# MEC1701Q register map
Vendor: Microchip Technology; Series: MEC1701; File version: 0
CPU: CM4 r1p0, little endian, MPU, FPU, 3 interrupt priority bits
Registers are 32-bit, read-write, reset 0x0 unless marked. A register's access mark holds for its fields unless they carry their own. Offsets are from the block's base; [hi:lo] are bit positions; 'fields as' and 'values as' point back to an identical list.

## RTC — This is the set of registers that are automatically counted by hardware every 1 second while the block is enabled to run and to update. These registers are: Seconds, Minutes, Hours, Day of Week, Day of Month, Month, and Year.
Base 0x400F5000; register names take the prefix RTC_
0x00 SEC 8-bit — Seconds Register
0x01 SEC_ALARM 8-bit — Seconds Alarm Register
0x02 MIN 8-bit — Minutes Register
0x03 MIN_ALARM 8-bit — Minutes Alarm Register
0x04 HR 8-bit — Hours Register
0x05 HR_ALARM 8-bit — Hours Alarm Register
0x06 DAY_OF_WK 8-bit — Day of Week Register
0x07 DAY_OF_MON 8-bit — Day of Month Register
0x08 MONTH 8-bit
0x09 YEAR 8-bit
0x0A REGA 8-bit — Register A
0x0B REGB 8-bit — Register B
0x0C REGC 8-bit — Register C
0x0D REGD 8-bit — Register D
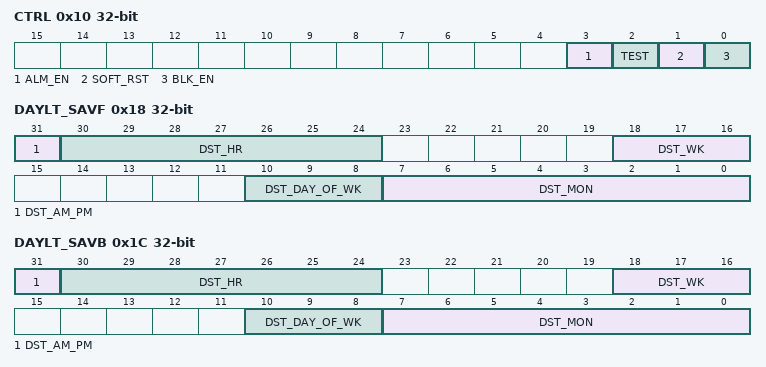
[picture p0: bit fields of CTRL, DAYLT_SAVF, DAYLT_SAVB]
0x10 CTRL — RTC Control Register
  [3] ALM_EN — ALM_EN 1=Enables the Alarm features, 0=Disables the Alarm features
  [2] TEST
  [1] SOFT_RST — SOFT_RST A '1' written to this bit position will trigger the RTC_RST reset, resetting the block and all registers except this one and the Test Register. This bit is self-clearing at the end of the reset, one cycle of Host Bus Clock later, and so requires no waiting.
  [0] BLK_EN — BLK_EN This bit must be '1' in order for the block to function internally. Registers may be initialized first, before setting this bit to '1' to start operation.
0x14 WK_ALARM — Week Alarm Register[7:0] - ALARM_DAY_OF_WEEK This register, if written to a value in the range 1- -7, will inhibit the Alarm interrupt unless this field matches the contents of the Day of Week Register also.
0x18 DAYLT_SAVF — Daylight Savings Forward Register
  [31] DST_AM_PM — This bit selects AM vs. PM, to match bit[7] of the Hours Register if 12-Hour mode is selected in Register B at the time of writing.
  [30:24] DST_HR — This field holds the matching value for bits[6:0] of the Hours register. The written value will be interpreted according to the 24/12 Hour mode and DM mode settings at the time of writing.
  [18:16] DST_WK — 5=Last week of month, 4 =Fourth week of month, 3=Third week of month, 2=Second week of month, 1=First week of month
  [10:8] DST_DAY_OF_WK — This field matches the Day of Week Register bits[2:0].
  [7:0] DST_MON — This field matches the Month Register.
0x1C DAYLT_SAVB — Daylight Savings Backward Register
  fields as DAYLT_SAVF

## TACH0 — This block monitors TACH output signals (or locked rotor signals) from various types of fans, and determines their speed.
Base 0x40006000; register names take the prefix TACH_
Same registers: TACH1 0x40006010, TACH2 0x40006020
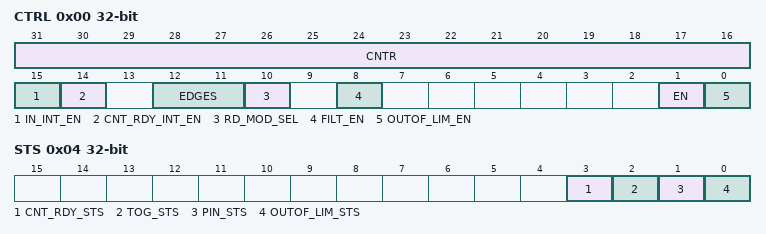
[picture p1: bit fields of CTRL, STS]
0x00 CTRL — TACHx Control Register
  [31:16] CNTR — This 16-bit field contains the latched value of the internal Tach pulse counter, which may be configured by the. Tach Reading Mode Select field to operate as a free-running counter or to be gated by the Tach input signal.
  [15] IN_INT_EN — IN_INT_EN 1=Enable Tach Input toggle interrupt from Tach block, 0=Disable Tach Input toggle interrupt from Tach block
  [14] CNT_RDY_INT_EN — CNT_RDY_INT_EN 1=Enable Count Ready interrupt from Tach block, 0=Disable Count Ready interrupt from Tach block
  [12:11] EDGES — EDGES A Tach signal is a square wave with a 50% duty cycle. Typically, two Tach periods represents one revolution of the fan. A Tach period consists of three Tach edges. This programmed value represents the number of Tach edges that will be used to determine the interval for which the number of 100kHz_Clk pulses will be counted. 11b=9 Tach edges (4 Tach periods). 10b=5 Tach edges (2 Tach periods). 01b=3 Tach edges (1 Tach period). 00b=2 Tach edges (1/2 Tach period)
  [10] RD_MOD_SEL — RD_MOD_SEL. 1=Counter is incremented on the rising edge of the 100kHz_Clk input. The counter is latched into the TACHX_COUNTER field and reset when the programmed number of edges is detected. 0=Counter is incremented when Tach Input transitions from low-tohigh state (default)
  [8] FILT_EN — FILT_EN This filter is used to remove high frequency glitches from Tach Input. When this filter is enabled, Tach input pulses less than two 100kHz_- Clk periods wide get filtered. 1= Filter enabled. 0= Filter disabled (default). It is recommended that the Tach input filter always be enabled.
  [1] EN — EN 1= TACH Monitoring enabled, clocks enabled. 0= TACH Idle, clocks gated
  [0] OUTOF_LIM_EN — OUTOF_LIM_EN This bit is used to enable the TACH_OUT_OF_LIMIT_STATUS bit in the TACHx Status Register to generate an interrupt event. 1=Enable interrupt output from Tach block. 0=Disable interrupt output from Tach block (default)
0x04 STS — TACHx Status Register
  [3] CNT_RDY_STS — CNT_RDY_STS 1=Reading ready, 0=Reading not ready
  [2] TOG_STS — TOG_STS 1=Tach Input changed state (this bit is set on a low-to-high or high-tolow transition), 0=Tach stable (R/WC)
  [1] PIN_STS — PIN_STS 1= Tach Input is high, 0= Tach Input is low
  [0] OUTOF_LIM_STS — OUTOF_LIM_STS 1=Tach is outside of limits, 0=Tach is within limits (R/WC)
0x08 LIM_HI reset 0xFFFF — TACH HIGH LIMIT Register
  [15:0] T_HIGH — This value is compared with the value in the TACHX_COUNTER field. If the value in the counter is greater than the value programmed in this register, the TACH_OUT_OF_LIMIT_STATUS bit will be set. The TACH_OUT_OF_LIMIT_STATUS status event may be enabled to generate an interrupt to the embedded controller via the TACH_OUT_OF_LIMIT_ENABLE bit in the TACHx Control Register.
0x0C LIM_LO — TACHx Low Limit Register
  [15:0] T_LOW — This value is compared with the value in the TACHX_COUNTER field of the TACHx Control Register. If the value in the counter is less than the value programmed in this register, the TACH_OUT_OF_LIMIT_STATUS bit will be set. The TACH_OUT_OF_LIMIT_STATUS status event may be enabled to generate an interrupt to the embedded controller via the TACH_OUT_OF_LIMIT_ENABLE bit in the TACHx. Control Register To disable the TACH_OUT_OF_LIMIT_STATUS low event, program 0000h into this register.

## Notices in the file
Copyright (c) 2017 Microchip Technology Inc.
SPDX-License-Identifier: Apache-2.0
Licensed under the Apache License, Version 2.0 (the "License");
you may not use this file except in compliance with the License.
You may obtain a copy of the License at
http://www.apache.org/licenses/LICENSE-2.0
Unless required by applicable law or agreed to in writing, software
distributed under the License is distributed on an "AS IS" BASIS,
WITHOUT WARRANTIES OR CONDITIONS OF ANY KIND, either express or implied.
See the License for the specific language governing permissions and
limitations under the License.
